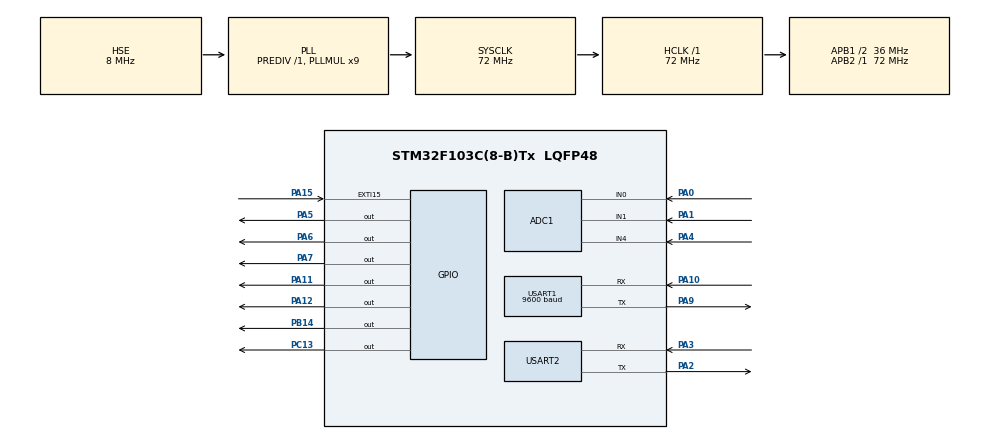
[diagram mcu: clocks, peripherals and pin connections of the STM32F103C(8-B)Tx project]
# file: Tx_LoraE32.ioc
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ADC1.Channel-0\#ChannelRegularConversion=ADC_CHANNEL_0
ADC1.ContinuousConvMode=DISABLE
ADC1.NbrOfConversionFlag=1
ADC1.Rank-0\#ChannelRegularConversion=1
ADC1.SamplingTime-0\#ChannelRegularConversion=ADC_SAMPLETIME_239CYCLES_5
ADC1.master=1
FREERTOS.Tasks01=LoRaTask,0,512,StartLoRaTask,Default,NULL,Dynamic,NULL,NULL;SensorTask,0,256,StartSensorTask,Default,NULL,Dynamic,NULL,NULL;IrrigationTask,0,512,StartIrrigationTask,Default,NULL,Dynamic,NULL,NULL
FREERTOS.configTOTAL_HEAP_SIZE=8192
Mcu.Family=STM32F1
Mcu.Name=STM32F103C(8-B)Tx
Mcu.Package=LQFP48
NVIC.EXTI15_10_IRQn=true\:5\:0\:false\:false\:true\:true\:true\:true
NVIC.PriorityGroup=NVIC_PRIORITYGROUP_4
NVIC.RTC_Alarm_IRQn=true\:5\:0\:false\:false\:true\:true\:true\:true
NVIC.RTC_IRQn=true\:5\:0\:false\:false\:true\:true\:true\:true
NVIC.TIM2_IRQn=true\:15\:0\:false\:false\:true\:false\:false\:true
NVIC.TimeBase=TIM2_IRQn
NVIC.TimeBaseIP=TIM2
NVIC.USART1_IRQn=true\:5\:0\:false\:false\:true\:true\:true\:true
PA0-WKUP.Signal=ADCx_IN0
PA1.Signal=ADCx_IN1
PA10.Mode=Asynchronous
PA10.Signal=USART1_RX
PA11.Signal=GPIO_Output
PA12.Signal=GPIO_Output
PA13.Mode=Serial_Wire
PA13.Signal=SYS_JTMS-SWDIO
PA14.Mode=Serial_Wire
PA14.Signal=SYS_JTCK-SWCLK
PA15.GPIO_ModeDefaultEXTI=GPIO_MODE_IT_FALLING
PA15.GPIO_PuPd=GPIO_PULLUP
PA15.Signal=GPXTI15
PA2.Mode=Asynchronous
PA2.Signal=USART2_TX
PA3.Mode=Asynchronous
PA3.Signal=USART2_RX
PA4.Signal=ADCx_IN4
PA5.PinState=GPIO_PIN_SET
PA5.Signal=GPIO_Output
PA6.PinState=GPIO_PIN_SET
PA6.Signal=GPIO_Output
PA7.PinState=GPIO_PIN_RESET
PA7.Signal=GPIO_Output
PA9.Mode=Asynchronous
PA9.Signal=USART1_TX
PB14.PinState=GPIO_PIN_RESET
PB14.Signal=GPIO_Output
PC13-TAMPER-RTC.PinState=GPIO_PIN_SET
PC13-TAMPER-RTC.Signal=GPIO_Output
PC14-OSC32_IN.Mode=LSE-External-Oscillator
PC14-OSC32_IN.Signal=RCC_OSC32_IN
PC15-OSC32_OUT.Mode=LSE-External-Oscillator
PC15-OSC32_OUT.Signal=RCC_OSC32_OUT
PD0-OSC_IN.Mode=HSE-External-Oscillator
PD0-OSC_IN.Signal=RCC_OSC_IN
PD1-OSC_OUT.Mode=HSE-External-Oscillator
PD1-OSC_OUT.Signal=RCC_OSC_OUT
ProjectManager.HeapSize=0x200
ProjectManager.StackSize=0x400
ProjectManager.TargetToolchain=STM32CubeIDE
RCC.ADCPresc=RCC_ADCPCLK2_DIV6
RCC.AHBFreq_Value=72000000
RCC.APB1CLKDivider=RCC_HCLK_DIV2
RCC.APB1Freq_Value=36000000
RCC.APB1TimFreq_Value=72000000
RCC.APB2Freq_Value=72000000
RCC.APB2TimFreq_Value=72000000
RCC.HCLKFreq_Value=72000000
RCC.PLLMUL=RCC_PLL_MUL9
RCC.PLLSourceVirtual=RCC_PLLSOURCE_HSE
RCC.RTCClockSelection=RCC_RTCCLKSOURCE_LSE
RCC.SYSCLKFreq_VALUE=72000000
RCC.SYSCLKSource=RCC_SYSCLKSOURCE_PLLCLK
RCC.USBFreq_Value=72000000
RTC.Format=RTC_FORMAT_BIN
RTC.Year=26
SH.ADCx_IN0.0=ADC1_IN0,IN0
SH.ADCx_IN1.0=ADC1_IN1,IN1
SH.ADCx_IN4.0=ADC1_IN4,IN4
TIM1.Prescaler=71
USART1.BaudRate=9600
USART1.VirtualMode=VM_ASYNC
USART2.VirtualMode=VM_ASYNC
VP_FREERTOS_VS_CMSIS_V2.Mode=CMSIS_V2
VP_RTC_VS_RTC_Activate.Mode=RTC_Enabled
VP_RTC_VS_RTC_Calendar.Mode=RTC_Calendar
VP_SYS_VS_tim2.Mode=TIM2
VP_TIM1_VS_ClockSourceINT.Mode=Internal
board=custom

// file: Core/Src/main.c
/* USER CODE BEGIN Header */
/**
  ******************************************************************************
  * @file           : main.c
  * @brief          : Main program body
  ******************************************************************************
  * @attention
  *
  * <h2><center>&copy; Copyright (c) 2025 STMicroelectronics.
  * All rights reserved.</center></h2>
  *
  * This software component is licensed by ST under BSD 3-Clause license,
  * the "License"; You may not use this file except in compliance with the
  * License. You may obtain a copy of the License at:
  *                        opensource.org/licenses/BSD-3-Clause
  *
  ******************************************************************************
  */
/* USER CODE END Header */
#include "main.h"
#include "cmsis_os2.h"

/* USER CODE BEGIN Includes */

#include "app_config.h"
#include "debug_console.h"
#include "app_tasks.h"
#include "system_manager.h"

/* USER CODE END Includes */

ADC_HandleTypeDef hadc1;

RTC_HandleTypeDef hrtc;

TIM_HandleTypeDef htim1;

UART_HandleTypeDef huart1;
UART_HandleTypeDef huart2;

osThreadId_t LoRaTaskHandle;
osThreadId_t SensorTaskHandle;
osThreadId_t IrrigationTaskHandle;

void SystemClock_Config(void);
static void MX_GPIO_Init(void);
static void MX_TIM1_Init(void);
static void MX_USART1_UART_Init(void);
static void MX_ADC1_Init(void);
static void MX_USART2_UART_Init(void);
static void MX_RTC_Init(void);
void StartLoRaTask(void *argument);
void StartSensorTask(void *argument);
void StartIrrigationTask(void *argument);

int main(void)
{

  /* MCU Configuration--------------------------------------------------------*/

  /* Reset of all peripherals, Initializes the Flash interface and the Systick. */
   HAL_Init();

  /* Configure the system clock */
  SystemClock_Config();

  /* Initialize all configured peripherals */
  MX_GPIO_Init();
  MX_TIM1_Init();
  MX_USART1_UART_Init();
  MX_ADC1_Init();
  MX_USART2_UART_Init();
  MX_RTC_Init();
  /* USER CODE BEGIN 2 */

  SystemManager_Init();

  DebugConsole_Print("\r\n====================\r\n");
  DebugConsole_Print("STM32 NODE START\r\n");
  DebugConsole_Print("====================\r\n");

  /* USER CODE END 2 */

  /* Initialize the CMSIS-RTOS2 kernel before creating RTOS objects. */
  if (osKernelInitialize() != osOK)
  {
    Error_Handler();
  }

  /* Create the thread(s). CMSIS-RTOS2 stack_size is expressed in bytes. */
  const osThreadAttr_t LoRaTask_attributes = {
    .name = "LoRaTask",
    .stack_size = 512U * 4U,	// 1 word = 4 byte
    .priority = (osPriority_t) osPriorityNormal
  };
  LoRaTaskHandle = osThreadNew(StartLoRaTask, NULL, &LoRaTask_attributes);

  const osThreadAttr_t SensorTask_attributes = {
    .name = "SensorTask",
    .stack_size = 256U * 4U,
    .priority = (osPriority_t) osPriorityNormal
  };
  SensorTaskHandle = osThreadNew(StartSensorTask, NULL, &SensorTask_attributes);

  const osThreadAttr_t IrrigationTask_attributes = {
    .name = "IrrigationTask",
    .stack_size = 512U * 4U,
    .priority = (osPriority_t) osPriorityNormal
  };
  IrrigationTaskHandle = osThreadNew(StartIrrigationTask, NULL, &IrrigationTask_attributes);

  if (LoRaTaskHandle == NULL || SensorTaskHandle == NULL || IrrigationTaskHandle == NULL)
  {
    Error_Handler();
  }

  /* Start scheduler */
  if (osKernelStart() != osOK)
  {
    Error_Handler();
  }

  /* We should never get here as control is now taken by the scheduler */
  /* Infinite loop */
  while (1)
  {

  }
}

void SystemClock_Config(void)
{
  RCC_OscInitTypeDef RCC_OscInitStruct = {0};
  RCC_ClkInitTypeDef RCC_ClkInitStruct = {0};
  RCC_PeriphCLKInitTypeDef PeriphClkInit = {0};

  /** Initializes the RCC Oscillators according to the specified parameters
  * in the RCC_OscInitTypeDef structure.
  */
  RCC_OscInitStruct.OscillatorType = RCC_OSCILLATORTYPE_HSE|RCC_OSCILLATORTYPE_LSE;
  RCC_OscInitStruct.HSEState = RCC_HSE_ON;
  RCC_OscInitStruct.HSEPredivValue = RCC_HSE_PREDIV_DIV1;
  RCC_OscInitStruct.LSEState = RCC_LSE_ON;
  RCC_OscInitStruct.HSIState = RCC_HSI_ON;
  RCC_OscInitStruct.PLL.PLLState = RCC_PLL_ON;
  RCC_OscInitStruct.PLL.PLLSource = RCC_PLLSOURCE_HSE;
  RCC_OscInitStruct.PLL.PLLMUL = RCC_PLL_MUL9;
  if (HAL_RCC_OscConfig(&RCC_OscInitStruct) != HAL_OK)
  {
    Error_Handler();
  }
  /** Initializes the CPU, AHB and APB buses clocks
  */
  RCC_ClkInitStruct.ClockType = RCC_CLOCKTYPE_HCLK|RCC_CLOCKTYPE_SYSCLK
                              |RCC_CLOCKTYPE_PCLK1|RCC_CLOCKTYPE_PCLK2;
  RCC_ClkInitStruct.SYSCLKSource = RCC_SYSCLKSOURCE_PLLCLK;
  RCC_ClkInitStruct.AHBCLKDivider = RCC_SYSCLK_DIV1;
  RCC_ClkInitStruct.APB1CLKDivider = RCC_HCLK_DIV2;
  RCC_ClkInitStruct.APB2CLKDivider = RCC_HCLK_DIV1;

  if (HAL_RCC_ClockConfig(&RCC_ClkInitStruct, FLASH_LATENCY_2) != HAL_OK)
  {
    Error_Handler();
  }
  PeriphClkInit.PeriphClockSelection = RCC_PERIPHCLK_RTC|RCC_PERIPHCLK_ADC;
  PeriphClkInit.RTCClockSelection = RCC_RTCCLKSOURCE_LSE;
  PeriphClkInit.AdcClockSelection = RCC_ADCPCLK2_DIV6;
  if (HAL_RCCEx_PeriphCLKConfig(&PeriphClkInit) != HAL_OK)
  {
    Error_Handler();
  }
}

static void MX_ADC1_Init(void)
{

  ADC_ChannelConfTypeDef sConfig = {0};

  /** Common config
  */
  hadc1.Instance = ADC1;
  hadc1.Init.ScanConvMode = ADC_SCAN_DISABLE;
  hadc1.Init.ContinuousConvMode = DISABLE;
  hadc1.Init.DiscontinuousConvMode = DISABLE;
  hadc1.Init.ExternalTrigConv = ADC_SOFTWARE_START;
  hadc1.Init.DataAlign = ADC_DATAALIGN_RIGHT;
  hadc1.Init.NbrOfConversion = 1;
  if (HAL_ADC_Init(&hadc1) != HAL_OK)
  {
    Error_Handler();
  }
  /** Configure Regular Channel
  */
  sConfig.Channel = ADC_CHANNEL_0;
  sConfig.Rank = ADC_REGULAR_RANK_1;
  sConfig.SamplingTime = ADC_SAMPLETIME_239CYCLES_5;
  if (HAL_ADC_ConfigChannel(&hadc1, &sConfig) != HAL_OK)
  {
    Error_Handler();
  }

}

static void MX_RTC_Init(void)
{

  RTC_TimeTypeDef sTime = {0};
  RTC_DateTypeDef DateToUpdate = {0};

  /** Initialize RTC Only
  */
  hrtc.Instance = RTC;
  hrtc.Init.AsynchPrediv = RTC_AUTO_1_SECOND;
  hrtc.Init.OutPut = RTC_OUTPUTSOURCE_NONE;
  if (HAL_RTC_Init(&hrtc) != HAL_OK)
  {
    Error_Handler();
  }

  /** Initialize RTC and set the Time and Date
  */
  sTime.Hours = 0;
  sTime.Minutes = 0;
  sTime.Seconds = 0;

  if (HAL_RTC_SetTime(&hrtc, &sTime, RTC_FORMAT_BIN) != HAL_OK)
  {
    Error_Handler();
  }
  DateToUpdate.WeekDay = RTC_WEEKDAY_MONDAY;
  DateToUpdate.Month = RTC_MONTH_JANUARY;
  DateToUpdate.Date = 1;
  DateToUpdate.Year = 26;

  if (HAL_RTC_SetDate(&hrtc, &DateToUpdate, RTC_FORMAT_BIN) != HAL_OK)
  {
    Error_Handler();
  }

}

static void MX_TIM1_Init(void)
{

  TIM_ClockConfigTypeDef sClockSourceConfig = {0};
  TIM_MasterConfigTypeDef sMasterConfig = {0};

  htim1.Instance = TIM1;
  htim1.Init.Prescaler = 71;
  htim1.Init.CounterMode = TIM_COUNTERMODE_UP;
  htim1.Init.Period = 65535;
  htim1.Init.ClockDivision = TIM_CLOCKDIVISION_DIV1;
  htim1.Init.RepetitionCounter = 0;
  htim1.Init.AutoReloadPreload = TIM_AUTORELOAD_PRELOAD_DISABLE;
  if (HAL_TIM_Base_Init(&htim1) != HAL_OK)
  {
    Error_Handler();
  }
  sClockSourceConfig.ClockSource = TIM_CLOCKSOURCE_INTERNAL;
  if (HAL_TIM_ConfigClockSource(&htim1, &sClockSourceConfig) != HAL_OK)
  {
    Error_Handler();
  }
  sMasterConfig.MasterOutputTrigger = TIM_TRGO_RESET;
  sMasterConfig.MasterSlaveMode = TIM_MASTERSLAVEMODE_DISABLE;
  if (HAL_TIMEx_MasterConfigSynchronization(&htim1, &sMasterConfig) != HAL_OK)
  {
    Error_Handler();
  }

}

static void MX_USART1_UART_Init(void)
{

  huart1.Instance = USART1;
  huart1.Init.BaudRate = 9600;
  huart1.Init.WordLength = UART_WORDLENGTH_8B;
  huart1.Init.StopBits = UART_STOPBITS_1;
  huart1.Init.Parity = UART_PARITY_NONE;
  huart1.Init.Mode = UART_MODE_TX_RX;
  huart1.Init.HwFlowCtl = UART_HWCONTROL_NONE;
  huart1.Init.OverSampling = UART_OVERSAMPLING_16;
  if (HAL_UART_Init(&huart1) != HAL_OK)
  {
    Error_Handler();
  }

}

static void MX_USART2_UART_Init(void)
{

  huart2.Instance = USART2;
  huart2.Init.BaudRate = 115200;
  huart2.Init.WordLength = UART_WORDLENGTH_8B;
  huart2.Init.StopBits = UART_STOPBITS_1;
  huart2.Init.Parity = UART_PARITY_NONE;
  huart2.Init.Mode = UART_MODE_TX_RX;
  huart2.Init.HwFlowCtl = UART_HWCONTROL_NONE;
  huart2.Init.OverSampling = UART_OVERSAMPLING_16;
  if (HAL_UART_Init(&huart2) != HAL_OK)
  {
    Error_Handler();
  }

}

static void MX_GPIO_Init(void)
{
  GPIO_InitTypeDef GPIO_InitStruct = {0};

  /* GPIO Ports Clock Enable */
  __HAL_RCC_GPIOC_CLK_ENABLE();
  __HAL_RCC_GPIOD_CLK_ENABLE();
  __HAL_RCC_GPIOA_CLK_ENABLE();
  __HAL_RCC_GPIOB_CLK_ENABLE();

  /*Configure GPIO pin Output Level */
  HAL_GPIO_WritePin(GPIOC, GPIO_PIN_13, GPIO_PIN_SET);

  /* Safe relay defaults: active-low valves OFF, active-high pump OFF. */
  HAL_GPIO_WritePin(GPIOA, GPIO_PIN_5|GPIO_PIN_6, VALVE_RELAY_OFF);
  HAL_GPIO_WritePin(GPIOA, GPIO_PIN_7, PUMP_RELAY_OFF);

  /*Configure LoRa mode pin Output Level */
  HAL_GPIO_WritePin(GPIOA, GPIO_PIN_11|GPIO_PIN_12, GPIO_PIN_RESET);

  /*Configure GPIO pin Output Level */
  HAL_GPIO_WritePin(GPIOB, GPIO_PIN_14, GPIO_PIN_RESET);

  /*Configure GPIO pin : PC13 */
  GPIO_InitStruct.Pin = GPIO_PIN_13;
  GPIO_InitStruct.Mode = GPIO_MODE_OUTPUT_PP;
  GPIO_InitStruct.Pull = GPIO_NOPULL;
  GPIO_InitStruct.Speed = GPIO_SPEED_FREQ_LOW;
  HAL_GPIO_Init(GPIOC, &GPIO_InitStruct);

  /*Configure GPIO pins : PA5 PA6 PA7 PA11
                           PA12 */
  GPIO_InitStruct.Pin = GPIO_PIN_5|GPIO_PIN_6|GPIO_PIN_7|GPIO_PIN_11
                          |GPIO_PIN_12;
  GPIO_InitStruct.Mode = GPIO_MODE_OUTPUT_PP;
  GPIO_InitStruct.Pull = GPIO_NOPULL;
  GPIO_InitStruct.Speed = GPIO_SPEED_FREQ_LOW;
  HAL_GPIO_Init(GPIOA, &GPIO_InitStruct);

  /*Configure GPIO pin : PB14 */
  GPIO_InitStruct.Pin = GPIO_PIN_14;
  GPIO_InitStruct.Mode = GPIO_MODE_OUTPUT_PP;
  GPIO_InitStruct.Pull = GPIO_NOPULL;
  GPIO_InitStruct.Speed = GPIO_SPEED_FREQ_LOW;
  HAL_GPIO_Init(GPIOB, &GPIO_InitStruct);

  /*Configure GPIO pin : PA15 */
  GPIO_InitStruct.Pin = GPIO_PIN_15;
  GPIO_InitStruct.Mode = GPIO_MODE_IT_FALLING;
  GPIO_InitStruct.Pull = GPIO_PULLUP;
  HAL_GPIO_Init(GPIOA, &GPIO_InitStruct);

  /* EXTI interrupt init*/
  HAL_NVIC_SetPriority(EXTI15_10_IRQn, 5, 0);
  HAL_NVIC_EnableIRQ(EXTI15_10_IRQn);

}

void StartLoRaTask(void *argument)
{
  /* USER CODE BEGIN 5 */
  AppTasks_RunLoRa(argument);
  /* USER CODE END 5 */
}

void StartSensorTask(void *argument)
{
  /* USER CODE BEGIN StartSensorTask */
  AppTasks_RunSensor(argument);
  /* USER CODE END StartSensorTask */
}

void StartIrrigationTask(void *argument)
{
  /* USER CODE BEGIN StartIrrigationTask */
  AppTasks_RunIrrigation(argument);
  /* USER CODE END StartIrrigationTask */
}

void HAL_TIM_PeriodElapsedCallback(TIM_HandleTypeDef *htim)
{
  if (htim->Instance == TIM2) {
    HAL_IncTick();
  }
}

void Error_Handler(void)
{
  __disable_irq();
  while (1)
  {
  }
}

/************************ (C) COPYRIGHT STMicroelectronics *****END OF FILE****/
